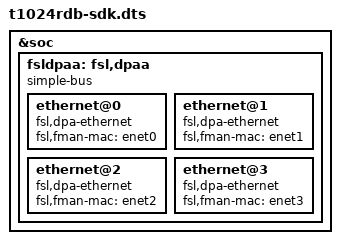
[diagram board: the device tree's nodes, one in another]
#include "t1024rdb.dts"

/include/ "qoriq-fman3-0-sdk.dtsi"
/include/ "qoriq-bman-portals-sdk.dtsi"
/include/ "qoriq-qman3-portals-sdk.dtsi"
/include/ "qoriq-qman3-ceetm0-8-sdk.dtsi"

&soc {
	fsldpaa: fsl,dpaa {
		compatible = "simple-bus", "fsl,dpaa";
		ethernet@0 {
			compatible = "fsl,dpa-ethernet";
			fsl,fman-mac = <&enet0>;
		};
		ethernet@1 {
			compatible = "fsl,dpa-ethernet";
			fsl,fman-mac = <&enet1>;
		};
		ethernet@2 {
			compatible = "fsl,dpa-ethernet";
			fsl,fman-mac = <&enet2>;
		};
		ethernet@3 {
			compatible = "fsl,dpa-ethernet";
			fsl,fman-mac = <&enet3>;
		};
	};
};
